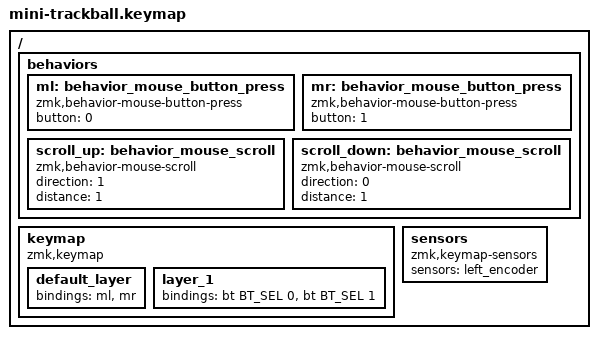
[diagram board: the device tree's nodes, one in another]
/*
 * Copyright (c) 2024 The ZMK Contributors
 *
 * SPDX-License-Identifier: MIT
 */

#include <behaviors.dtsi>
#include <dt-bindings/zmk/keys.h>
#include <dt-bindings/zmk/bt.h>
#include <dt-bindings/zmk/mouse.h>

/ {
    behaviors {
        // Mouse click behaviors
        ml: behavior_mouse_button_press {
            compatible = "zmk,behavior-mouse-button-press";
            #binding-cells = <0>;
            button = <0>; // Left click
        };
        
        mr: behavior_mouse_button_press {
            compatible = "zmk,behavior-mouse-button-press";
            #binding-cells = <0>;
            button = <1>; // Right click
        };
        
        // Scroll behaviors for encoder
        scroll_up: behavior_mouse_scroll {
            compatible = "zmk,behavior-mouse-scroll";
            #binding-cells = <0>;
            direction = <1>; // Up
            distance = <1>;
        };
        
        scroll_down: behavior_mouse_scroll {
            compatible = "zmk,behavior-mouse-scroll";
            #binding-cells = <0>;
            direction = <0>; // Down
            distance = <1>;
        };
    };

    keymap {
        compatible = "zmk,keymap";

        default_layer {
            // Mouse buttons
            bindings = <
                &ml &mr
            >;
        };

        layer_1 {
            // Function layer (Bluetooth switching)
            bindings = <
                &bt BT_SEL 0 &bt BT_SEL 1
            >;
        };
    };
    
    sensors {
        compatible = "zmk,keymap-sensors";
        sensors = <&left_encoder>;
    };
}; 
